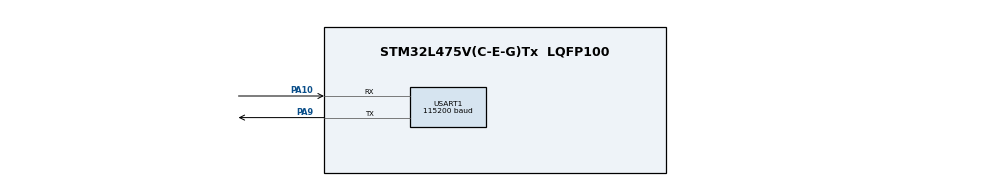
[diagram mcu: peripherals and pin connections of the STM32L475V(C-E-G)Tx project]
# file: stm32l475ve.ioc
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Mcu.Family=STM32L4
Mcu.Name=STM32L475V(C-E-G)Tx
Mcu.Package=LQFP100
NVIC.PriorityGroup=NVIC_PRIORITYGROUP_4
NVIC.USART1_IRQn=true\:0\:0\:false\:false\:true\:true\:true
PA10.Mode=Asynchronous
PA10.Signal=USART1_RX
PA13\ (JTMS-SWDIO).Mode=Serial_Wire
PA13\ (JTMS-SWDIO).Signal=SYS_JTMS-SWDIO
PA14\ (JTCK-SWCLK).Mode=Serial_Wire
PA14\ (JTCK-SWCLK).Signal=SYS_JTCK-SWCLK
PA9.Mode=Asynchronous
PA9.Signal=USART1_TX
PC14-OSC32_IN\ (PC14).Mode=LSE-External-Oscillator
PC14-OSC32_IN\ (PC14).Signal=RCC_OSC32_IN
PC15-OSC32_OUT\ (PC15).Mode=LSE-External-Oscillator
PC15-OSC32_OUT\ (PC15).Signal=RCC_OSC32_OUT
PH0-OSC_IN\ (PH0).Mode=HSE-External-Oscillator
PH0-OSC_IN\ (PH0).Signal=RCC_OSC_IN
PH1-OSC_OUT\ (PH1).Mode=HSE-External-Oscillator
PH1-OSC_OUT\ (PH1).Signal=RCC_OSC_OUT
ProjectManager.HeapSize=0x200
ProjectManager.StackSize=0x400
ProjectManager.TargetToolchain=MDK-ARM V5
RCC.ADCFreq_Value=32000000
RCC.AHBFreq_Value=80000000
RCC.APB1Freq_Value=80000000
RCC.APB1TimFreq_Value=80000000
RCC.APB2Freq_Value=80000000
RCC.APB2TimFreq_Value=80000000
RCC.CortexFreq_Value=80000000
RCC.HCLKFreq_Value=80000000
RCC.HSE_VALUE=8000000
RCC.HSI_VALUE=16000000
RCC.MSI_VALUE=4000000
RCC.PLLN=20
RCC.PLLSourceVirtual=RCC_PLLSOURCE_HSE
RCC.RTCClockSelection=RCC_RTCCLKSOURCE_LSE
RCC.SYSCLKFreq_VALUE=80000000
RCC.SYSCLKSource=RCC_SYSCLKSOURCE_PLLCLK
RCC.USBFreq_Value=32000000
RCC.VCOOutputFreq_Value=160000000
USART1.BaudRate=115200
USART1.VirtualMode-Asynchronous=VM_ASYNC
board=custom

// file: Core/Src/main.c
/* USER CODE BEGIN Header */
/**
  ******************************************************************************
  * @file           : main.c
  * @brief          : Main program body
  ******************************************************************************
  * @attention
  *
  * <h2><center>&copy; Copyright (c) 2022 STMicroelectronics.
  * All rights reserved.</center></h2>
  *
  * This software component is licensed by ST under BSD 3-Clause license,
  * the "License"; You may not use this file except in compliance with the
  * License. You may obtain a copy of the License at:
  *                        opensource.org/licenses/BSD-3-Clause
  *
  ******************************************************************************
  */
/* USER CODE END Header */
#include "main.h"
#include "usart.h"
#include "gpio.h"

/* USER CODE BEGIN Includes */
#include <stdio.h>
#include "timer_task.h"
#include "queue.h"
/* USER CODE END Includes */

void SystemClock_Config(void);

/* USER CODE BEGIN 0 */

struct timer_kk
{
  uint8_t  id;
  uint16_t delay_ms;
};

struct timer_kk tt_test = {0};

QueueHandle_t timer_queue = NULL;

void QueueTest(TIMER_ID id, uint16_t delay)
{
  struct timer_kk gg_test = {0};

  gg_test.id = id;
  gg_test.delay_ms = delay;

  QueueSend(timer_queue, &gg_test);
}

/* USER CODE END 0 */

int main(void)
{

  /* MCU Configuration--------------------------------------------------------*/

  /* Reset of all peripherals, Initializes the Flash interface and the Systick. */

  LL_APB2_GRP1_EnableClock(LL_APB2_GRP1_PERIPH_SYSCFG);
  LL_APB1_GRP1_EnableClock(LL_APB1_GRP1_PERIPH_PWR);

  NVIC_SetPriorityGrouping(NVIC_PRIORITYGROUP_4);

  /* System interrupt init*/
  /* SysTick_IRQn interrupt configuration */
  NVIC_SetPriority(SysTick_IRQn, NVIC_EncodePriority(NVIC_GetPriorityGrouping(),15, 0));

  /* Configure the system clock */
  SystemClock_Config();

  /* USER CODE BEGIN SysInit */
  LL_SYSTICK_EnableIT();
  /* USER CODE END SysInit */

  /* Initialize all configured peripherals */
  MX_GPIO_Init();
  MX_USART1_UART_Init();
  /* USER CODE BEGIN 2 */
  printf("Init Complete!\r\n");

  timer_queue = QueueCreate(8, sizeof(struct timer_kk));
  TIMER_ID timer_test_print = 0x00;

  timer_test_print = timer_task_register(RUN_LOOP, 1000, QueueTest);
  timer_task_start(timer_test_print);
  /* USER CODE END 2 */

  /* Infinite loop */
  while (1)
  {

    /* USER CODE BEGIN 3 */
	if(QueuePeek(timer_queue, &tt_test))
	{
		printf("QueuePeek :    %d, %d\n", tt_test.id, tt_test.delay_ms);
	}
	if(QueueReceive(timer_queue, &tt_test))
	{
		printf("QueueReceive : %d, %d\n", tt_test.id, tt_test.delay_ms);
	}

  }
  /* USER CODE END 3 */
}

void SystemClock_Config(void)
{
  LL_FLASH_SetLatency(LL_FLASH_LATENCY_4);
  while(LL_FLASH_GetLatency()!= LL_FLASH_LATENCY_4)
  {
  }
  LL_PWR_SetRegulVoltageScaling(LL_PWR_REGU_VOLTAGE_SCALE1);
  LL_RCC_HSE_Enable();

   /* Wait till HSE is ready */
  while(LL_RCC_HSE_IsReady() != 1)
  {

  }
  LL_RCC_PLL_ConfigDomain_SYS(LL_RCC_PLLSOURCE_HSE, LL_RCC_PLLM_DIV_1, 20, LL_RCC_PLLR_DIV_2);
  LL_RCC_PLL_EnableDomain_SYS();
  LL_RCC_PLL_Enable();

   /* Wait till PLL is ready */
  while(LL_RCC_PLL_IsReady() != 1)
  {

  }
  LL_RCC_SetSysClkSource(LL_RCC_SYS_CLKSOURCE_PLL);

   /* Wait till System clock is ready */
  while(LL_RCC_GetSysClkSource() != LL_RCC_SYS_CLKSOURCE_STATUS_PLL)
  {

  }
  LL_RCC_SetAHBPrescaler(LL_RCC_SYSCLK_DIV_1);
  LL_RCC_SetAPB1Prescaler(LL_RCC_APB1_DIV_1);
  LL_RCC_SetAPB2Prescaler(LL_RCC_APB2_DIV_1);

  LL_Init1msTick(80000000);

  LL_SetSystemCoreClock(80000000);
}

void Error_Handler(void)
{
  __disable_irq();
  while (1)
  {
  }
}

/************************ (C) COPYRIGHT STMicroelectronics *****END OF FILE****/
